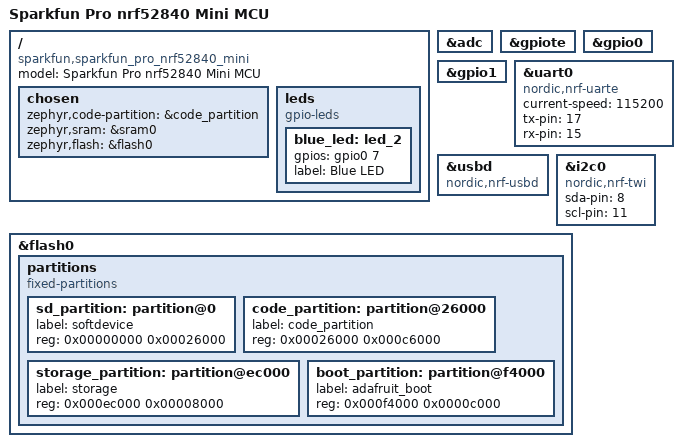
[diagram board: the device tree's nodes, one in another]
/*
 * Copyright (c) 2020 The ZMK Contributors
 * SPDX-License-Identifier: MIT
 */

/dts-v1/;
#include <nordic/nrf52840_qiaa.dtsi>
#include "arduino_pro_micro_pins.dtsi"

/ {
	model = "Sparkfun Pro nrf52840 Mini MCU";
	compatible = "sparkfun,sparkfun_pro_nrf52840_mini";

	chosen {
		zephyr,code-partition = &code_partition;
		zephyr,sram = &sram0;
		zephyr,flash = &flash0;
	};

	leds {
		compatible = "gpio-leds";
		blue_led: led_2 {
			gpios = <&gpio0 7 GPIO_ACTIVE_HIGH>;
			label = "Blue LED";
		};
	};

};

&adc {
	status = "okay";
};

&gpiote {
	status = "okay";
};

&gpio0 {
	status = "okay";
};

&gpio1 {
	status = "okay";
};

&uart0 {
	compatible = "nordic,nrf-uarte";
	status = "okay";
	current-speed = <115200>;
	tx-pin = <17>;
	rx-pin = <15>;
};

&usbd {
	compatible = "nordic,nrf-usbd";
	status = "okay";
};

&i2c0 {
	compatible = "nordic,nrf-twi";
	sda-pin = <8>;
	scl-pin = <11>;
};


&flash0 {
	/*
	 * For more information, see:
	 * http://docs.zephyrproject.org/latest/devices/dts/flash_partitions.html
	 */
	partitions {
		compatible = "fixed-partitions";
		#address-cells = <1>;
		#size-cells = <1>;

		sd_partition: partition@0 {
			label = "softdevice";
			reg = <0x00000000 0x00026000>;
		};
		code_partition: partition@26000 {
			label = "code_partition";
			reg = <0x00026000 0x000c6000>;
		};

		/*
		 * The flash starting at 0x000ec000 and ending at
		 * 0x000f3fff is reserved for use by the application.
		 */

		/*
		 * Storage partition will be used by FCB/LittleFS/NVS
		 * if enabled.
		 */
		storage_partition: partition@ec000 {
			label = "storage";
			reg = <0x000ec000 0x00008000>;
		};

		boot_partition: partition@f4000 {
			label = "adafruit_boot";
			reg = <0x000f4000 0x0000c000>;
		};
	};
};
